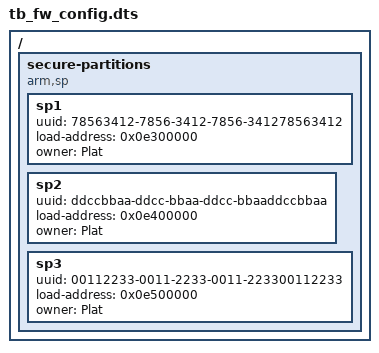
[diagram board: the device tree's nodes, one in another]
/dts-v1/;
/ {
	secure-partitions {
		compatible = "arm,sp";

		sp1 {
			uuid = "78563412-7856-3412-7856-341278563412";
			load-address = <0x0e300000>;
			owner = "Plat";
		};

		sp2 {
			uuid = "ddccbbaa-ddcc-bbaa-ddcc-bbaaddccbbaa";
			load-address = <0x0e400000>;
			owner = "Plat";
		};

		sp3 {
			uuid = "00112233-0011-2233-0011-223300112233";
			load-address = <0x0e500000>;
			owner = "Plat";
		};
	};
};
